# CH32V307xx register map
Vendor: WCH Ltd.; File version: 1.0
Registers are 32-bit, read-write, reset 0x0 unless marked. A register's access mark holds for its fields unless they carry their own. Offsets are from the block's base; [hi:lo] are bit positions; {n}, {i} and the like mark numbered series; 'fields as' and 'values as' point back to an identical list.

## USB_OTG_FS — USB FS OTG register
Base 0x50000000
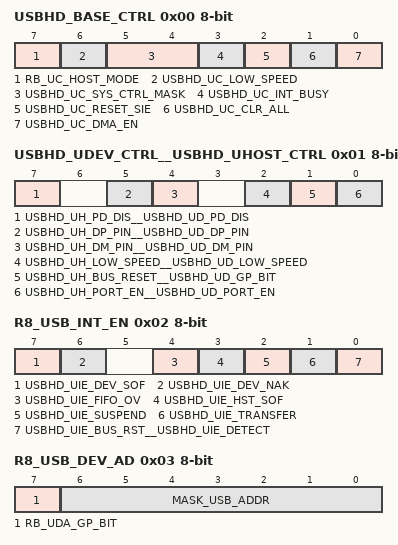
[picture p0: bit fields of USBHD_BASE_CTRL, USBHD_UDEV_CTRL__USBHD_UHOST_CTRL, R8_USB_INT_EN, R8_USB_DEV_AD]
0x00 USBHD_BASE_CTRL 8-bit — USB base control
  [7] RB_UC_HOST_MODE — enable USB host mode: 0=device mode, 1=host mode
  [6] USBHD_UC_LOW_SPEED — enable USB low speed: 0=12Mbps, 1=1.5Mbps
  [5:4] USBHD_UC_SYS_CTRL_MASK — USB device enable and internal pullup resistance enable
  [3] USBHD_UC_INT_BUSY — enable automatic responding busy for device mode or automatic pause for host mode during interrupt flag UIF_TRANSFER valid
  [2] USBHD_UC_RESET_SIE — force reset USB SIE, need software clear
  [1] USBHD_UC_CLR_ALL — force clear FIFO and count of USB
  [0] USBHD_UC_DMA_EN — DMA enable and DMA interrupt enable for USB
0x01 USBHD_UDEV_CTRL__USBHD_UHOST_CTRL 8-bit reset 0x6 — USB device/host physical prot control
  [7] USBHD_UH_PD_DIS__USBHD_UD_PD_DIS — disable USB UDP/UDM pulldown resistance: 0=enable pulldown, 1=disable
  [5] USBHD_UH_DP_PIN__USBHD_UD_DP_PIN read-opnly — USB device enable and internal pullup resistance enable
  [4] USBHD_UH_DM_PIN__USBHD_UD_DM_PIN read-opnly — ReadOnly: indicate current UDM pin level
  [2] USBHD_UH_LOW_SPEED__USBHD_UD_LOW_SPEED — enable USB port low speed: 0=full speed, 1=low speed
  [1] USBHD_UH_BUS_RESET__USBHD_UD_GP_BIT — force clear FIFO and count of USB
  [0] USBHD_UH_PORT_EN__USBHD_UD_PORT_EN — enable USB port: 0=disable, 1=enable port, automatic disabled if USB device detached
0x02 R8_USB_INT_EN 8-bit — USB interrupt enable
  [7] USBHD_UIE_DEV_SOF — enable interrupt for SOF received for USB device mode
  [6] USBHD_UIE_DEV_NAK — enable interrupt for NAK responded for USB device mode
  [4] USBHD_UIE_FIFO_OV — enable interrupt for FIFO overflow
  [3] USBHD_UIE_HST_SOF — enable interrupt for host SOF timer action for USB host mode
  [2] USBHD_UIE_SUSPEND — enable interrupt for USB suspend or resume event
  [1] USBHD_UIE_TRANSFER — enable interrupt for USB transfer completion
  [0] USBHD_UIE_BUS_RST__USBHD_UIE_DETECT — enable interrupt for USB bus reset event for USB device mode
0x03 R8_USB_DEV_AD 8-bit — USB device address
  [7] RB_UDA_GP_BIT — general purpose bit
  [6:0] MASK_USB_ADDR — bit mask for USB device address
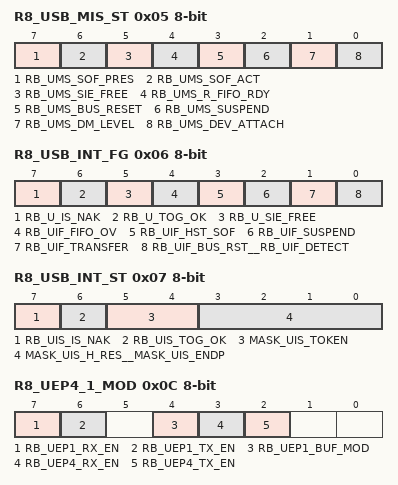
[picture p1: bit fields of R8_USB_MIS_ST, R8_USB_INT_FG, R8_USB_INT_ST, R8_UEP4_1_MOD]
0x05 R8_USB_MIS_ST 8-bit ro — USB miscellaneous status
  [7] RB_UMS_SOF_PRES — RO, indicate host SOF timer presage status
  [6] RB_UMS_SOF_ACT — RO, indicate host SOF timer action status for USB host
  [5] RB_UMS_SIE_FREE — RO, indicate USB SIE free status
  [4] RB_UMS_R_FIFO_RDY — RO, indicate USB receiving FIFO ready status (not empty)
  [3] RB_UMS_BUS_RESET — RO, indicate USB bus reset status
  [2] RB_UMS_SUSPEND — RO, indicate USB suspend status
  [1] RB_UMS_DM_LEVEL — RO, indicate UDM level saved at device attached to USB host
  [0] RB_UMS_DEV_ATTACH — RO, indicate device attached status on USB host
0x06 R8_USB_INT_FG 8-bit — USB interrupt flag
  [7] RB_U_IS_NAK ro — RO, indicate current USB transfer is NAK received
  [6] RB_U_TOG_OK ro — RO, indicate current USB transfer toggle is OK
  [5] RB_U_SIE_FREE ro — RO, indicate USB SIE free status
  [4] RB_UIF_FIFO_OV — FIFO overflow interrupt flag for USB, direct bit address clear or write 1 to clear
  [3] RB_UIF_HST_SOF — host SOF timer interrupt flag for USB host, direct bit address clear or write 1 to clear
  [2] RB_UIF_SUSPEND — USB suspend or resume event interrupt flag, direct bit address clear or write 1 to clear
  [1] RB_UIF_TRANSFER — USB transfer completion interrupt flag, direct bit address clear or write 1 to clear
  [0] RB_UIF_BUS_RST__RB_UIF_DETECT — bus reset event interrupt flag for USB device mode, direct bit address clear or write 1 to clear;device detected event interrupt flag for USB host mode, direct bit address clear or write 1 to clear
0x07 R8_USB_INT_ST 8-bit ro — USB interrupt status
  [7] RB_UIS_IS_NAK — RO, indicate current USB transfer is NAK received for USB device mode
  [6] RB_UIS_TOG_OK — RO, indicate current USB transfer toggle is OK
  [5:4] MASK_UIS_TOKEN — RO, bit mask of current token PID code received for USB device mode
  [3:0] MASK_UIS_H_RES__MASK_UIS_ENDP — RO, bit mask of current transfer handshake response for USB host mode: 0000=no response, time out from device, others=handshake response PID received;RO, bit mask of current transfer endpoint number for USB device mode
0x08 R16_USB_RX_LEN 16-bit ro — USB receiving length
0x0C R8_UEP4_1_MOD 8-bit — endpoint 4/1 mode
  [7] RB_UEP1_RX_EN — enable USB endpoint 1 receiving (OUT)
  [6] RB_UEP1_TX_EN — enable USB endpoint 1 transmittal (IN)
  [4] RB_UEP1_BUF_MOD — buffer mode of USB endpoint 1
  [3] RB_UEP4_RX_EN — enable USB endpoint 4 receiving (OUT)
  [2] RB_UEP4_TX_EN — enable USB endpoint 4 transmittal (IN)
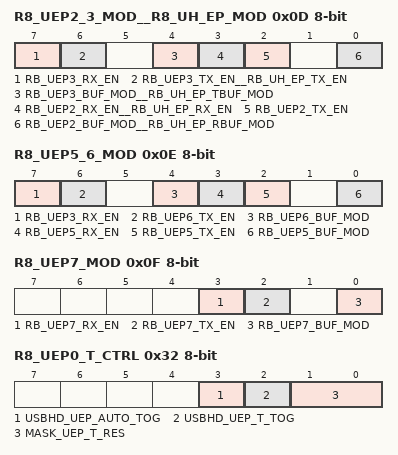
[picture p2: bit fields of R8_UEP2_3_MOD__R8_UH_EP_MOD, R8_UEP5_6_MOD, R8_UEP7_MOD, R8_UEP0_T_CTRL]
0x0D R8_UEP2_3_MOD__R8_UH_EP_MOD 8-bit — endpoint 2/3 mode;host endpoint mode
  [7] RB_UEP3_RX_EN — enable USB endpoint 3 receiving (OUT)
  [6] RB_UEP3_TX_EN__RB_UH_EP_TX_EN — enable USB endpoint 3 transmittal (IN);enable USB host OUT endpoint transmittal
  [4] RB_UEP3_BUF_MOD__RB_UH_EP_TBUF_MOD — buffer mode of USB endpoint 3;buffer mode of USB host OUT endpoint
  [3] RB_UEP2_RX_EN__RB_UH_EP_RX_EN — enable USB endpoint 2 receiving (OUT);enable USB host IN endpoint receiving
  [2] RB_UEP2_TX_EN — enable USB endpoint 2 transmittal (IN)
  [0] RB_UEP2_BUF_MOD__RB_UH_EP_RBUF_MOD — buffer mode of USB endpoint 2;buffer mode of USB host IN endpoint
0x0E R8_UEP5_6_MOD 8-bit — endpoint 5/6 mode
  [7] RB_UEP3_RX_EN — enable USB endpoint 6 receiving (OUT)
  [6] RB_UEP6_TX_EN — enable USB endpoint 6 transmittal (IN)
  [4] RB_UEP6_BUF_MOD — buffer mode of USB endpoint 6
  [3] RB_UEP5_RX_EN — enable USB endpoint 5 receiving (OUT)
  [2] RB_UEP5_TX_EN — enable USB endpoint 5 transmittal (IN)
  [0] RB_UEP5_BUF_MOD — buffer mode of USB endpoint 5
0x0F R8_UEP7_MOD 8-bit — endpoint 7 mode
  [3] RB_UEP7_RX_EN — enable USB endpoint 7 receiving (OUT)
  [2] RB_UEP7_TX_EN — enable USB endpoint 7 transmittal (IN)
  [0] RB_UEP7_BUF_MOD — buffer mode of USB endpoint 7
0x10 R32_UEP0_DMA — endpoint 0 DMA buffer address
0x14 R32_UEP1_DMA — endpoint 1 DMA buffer address
0x18 R32_UEP2_DMA__R32_UH_RX_DMA — endpoint 2 DMA buffer address;host rx endpoint buffer high address
0x1C R32_UEP3_DMA__R32_UH_TX_DMA — endpoint 3 DMA buffer address;host tx endpoint buffer high address
{0x10+4i} R32_UEP{i}_DMA (i=4..7) — endpoint {i} DMA buffer address
0x30 R8_UEP0_T_LEN 8-bit — endpoint 0 transmittal length
0x32 R8_UEP0_T_CTRL 8-bit — endpoint 0 control
  [3] USBHD_UEP_AUTO_TOG — enable automatic toggle after successful transfer completion on endpoint 1/2/3: 0=manual toggle, 1=automatic toggle
  [2] USBHD_UEP_T_TOG — prepared data toggle flag of USB endpoint X transmittal (IN): 0=DATA0, 1=DATA1
  [1:0] MASK_UEP_T_RES — bit mask of handshake response type for USB endpoint X transmittal (IN)
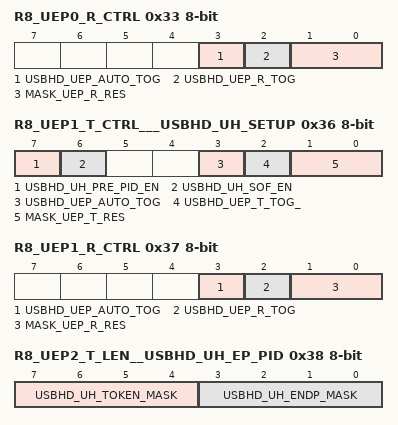
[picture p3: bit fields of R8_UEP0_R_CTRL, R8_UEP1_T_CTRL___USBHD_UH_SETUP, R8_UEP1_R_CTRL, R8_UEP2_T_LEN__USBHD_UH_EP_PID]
0x33 R8_UEP0_R_CTRL 8-bit — endpoint 0 control
  [3] USBHD_UEP_AUTO_TOG — enable automatic toggle after successful transfer completion on endpoint 1/2/3: 0=manual toggle, 1=automatic toggle
  [2] USBHD_UEP_R_TOG — expected data toggle flag of USB endpoint X receiving (OUT): 0=DATA0, 1=DATA1
  [1:0] MASK_UEP_R_RES — bit mask of handshake response type for USB endpoint X receiving (OUT)
0x34 R8_UEP1_T_LEN 8-bit — endpoint 1 transmittal length
0x36 R8_UEP1_T_CTRL___USBHD_UH_SETUP 8-bit — endpoint 1 control
  [7] USBHD_UH_PRE_PID_EN — USB host PRE PID enable for low speed device via hub
  [6] USBHD_UH_SOF_EN — USB host automatic SOF enable
  [3] USBHD_UEP_AUTO_TOG — enable automatic toggle after successful transfer completion on endpoint 1/2/3: 0=manual toggle, 1=automatic toggle
  [2] USBHD_UEP_T_TOG_ — prepared data toggle flag of USB endpoint X transmittal (IN): 0=DATA0, 1=DATA1
  [1:0] MASK_UEP_T_RES — bit mask of handshake response type for USB endpoint X transmittal (IN)
0x37 R8_UEP1_R_CTRL 8-bit — endpoint 1 control
  fields as R8_UEP0_R_CTRL
0x38 R8_UEP2_T_LEN__USBHD_UH_EP_PID 8-bit — endpoint 2 transmittal length
  [7:4] USBHD_UH_TOKEN_MASK — bit mask of token PID for USB host transfer
  [3:0] USBHD_UH_ENDP_MASK — bit mask of endpoint number for USB host transfer
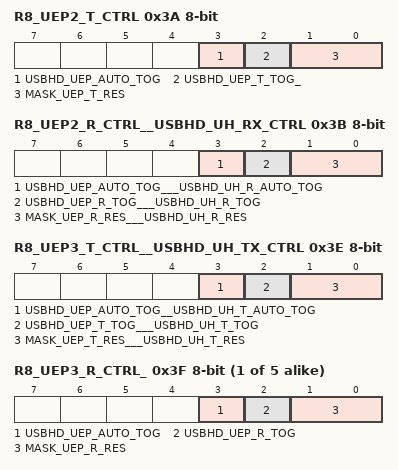
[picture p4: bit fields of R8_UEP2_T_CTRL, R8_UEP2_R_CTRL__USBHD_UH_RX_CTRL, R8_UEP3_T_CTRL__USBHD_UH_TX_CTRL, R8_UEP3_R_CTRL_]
0x3A R8_UEP2_T_CTRL 8-bit — endpoint 2 control
  [3] USBHD_UEP_AUTO_TOG — enable automatic toggle after successful transfer completion on endpoint 1/2/3: 0=manual toggle, 1=automatic toggle
  [2] USBHD_UEP_T_TOG_ — prepared data toggle flag of USB endpoint X transmittal (IN): 0=DATA0, 1=DATA1
  [1:0] MASK_UEP_T_RES — bit mask of handshake response type for USB endpoint X transmittal (IN)
0x3B R8_UEP2_R_CTRL__USBHD_UH_RX_CTRL 8-bit — endpoint 2 control
  [3] USBHD_UEP_AUTO_TOG___USBHD_UH_R_AUTO_TOG — enable automatic toggle after successful transfer completion on endpoint 1/2/3: 0=manual toggle, 1=automatic toggle
  [2] USBHD_UEP_R_TOG___USBHD_UH_R_TOG — expected data toggle flag of USB endpoint X receiving (OUT): 0=DATA0, 1=DATA1
  [1:0] MASK_UEP_R_RES___USBHD_UH_R_RES — bit mask of handshake response type for USB endpoint X receiving (OUT)
0x3C R8_UEP3_T_LEN__USBHD_UH_TX_LEN 8-bit — endpoint 3 transmittal length
0x3E R8_UEP3_T_CTRL__USBHD_UH_TX_CTRL 8-bit — endpoint 3 control
  [3] USBHD_UEP_AUTO_TOG__USBHD_UH_T_AUTO_TOG — enable automatic toggle after successful transfer completion on endpoint 1/2/3: 0=manual toggle, 1=automatic toggle
  [2] USBHD_UEP_T_TOG___USBHD_UH_T_TOG — prepared data toggle flag of USB endpoint X transmittal (IN): 0=DATA0, 1=DATA1
  [1:0] MASK_UEP_T_RES___USBHD_UH_T_RES — bit mask of handshake response type for USB endpoint X transmittal (IN)
{0x33+4i} R8_UEP{i}_R_CTRL_ 8-bit (i=3..7) — endpoint {i} control
  fields as R8_UEP0_R_CTRL
{0x30+4i} R8_UEP{i}_T_LEN 8-bit (i=4..7) — endpoint {i} transmittal length
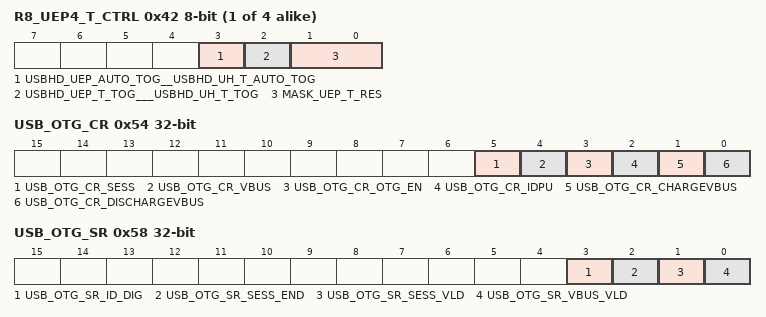
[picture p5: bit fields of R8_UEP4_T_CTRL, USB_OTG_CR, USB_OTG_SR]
{0x32+4i} R8_UEP{i}_T_CTRL 8-bit (i=4..7) — endpoint {i} control
  [3] USBHD_UEP_AUTO_TOG__USBHD_UH_T_AUTO_TOG — enable automatic toggle after successful transfer completion on endpoint 1/2/3: 0=manual toggle, 1=automatic toggle
  [2] USBHD_UEP_T_TOG___USBHD_UH_T_TOG — prepared data toggle flag of USB endpoint X transmittal (IN): 0=DATA0, 1=DATA1
  [1:0] MASK_UEP_T_RES — bit mask of handshake response type for USB endpoint X transmittal (IN)
0x54 USB_OTG_CR — usb otg control
  [5] USB_OTG_CR_SESS — usb otg control
  [4] USB_OTG_CR_VBUS — usb otg control
  [3] USB_OTG_CR_OTG_EN — usb otg control
  [2] USB_OTG_CR_IDPU — usb otg control
  [1] USB_OTG_CR_CHARGEVBUS — usb otg control
  [0] USB_OTG_CR_DISCHARGEVBUS — usb otg control
0x58 USB_OTG_SR — usb otg status
  [3] USB_OTG_SR_ID_DIG — usb otg status
  [2] USB_OTG_SR_SESS_END — usb otg status
  [1] USB_OTG_SR_SESS_VLD — usb otg status
  [0] USB_OTG_SR_VBUS_VLD — usb otg status
